# STM32H7RSxx register map
File version: 0.2
CPU: CM7 r0p1, little endian, MPU, FPU, 4 interrupt priority bits
Registers are 32-bit, read-write, reset 0x0 unless marked. A register's access mark holds for its fields unless they carry their own. Offsets are from the block's base; [hi:lo] are bit positions.

## TIM6 — Basic timers
Base 0x40001000
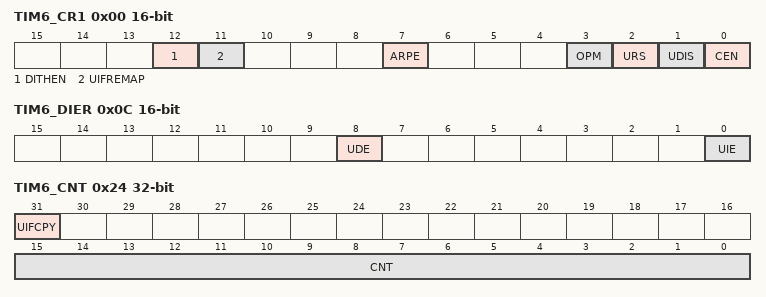
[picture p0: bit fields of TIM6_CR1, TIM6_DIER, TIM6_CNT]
0x00 TIM6_CR1 16-bit — TIM6 control register 1
  [12] DITHEN — Dithering enable Note: The DITHEN bit can only be modified when CEN bit is reset.
    0=Dithering disabled; 1=Dithering enabled
  [11] UIFREMAP — UIF status bit remapping
    0=No remapping. UIF status bit is not copied to TIMx_CNT register bit 31.; 1=Remapping enabled. UIF status bit is copied to TIMx_CNT register bit 31.
  [7] ARPE — Auto-reload preload enable
    0=TIMx_ARR register is not buffered; 1=TIMx_ARR register is buffered
  [3] OPM — One-pulse mode
    0=Counter is not stopped at update event; 1=Counter stops counting at the next update event (clearing the CEN bit)
  [2] URS — Update request source This bit is set and cleared by software to select the UEV event sources. Counter overflow/underflow Setting the UG bit Update generation through the slave mode controller
    0=Any of the following events generates an update interrupt or DMA request if enabled. These events can be:; 1=Only counter overflow/underflow generates an update interrupt or DMA request if enabled
  [1] UDIS — Update disable This bit is set and cleared by software to enable/disable UEV event generation. Counter overflow/underflow Setting the UG bit Update generation through the slave mode controller Buffered registers are then loaded with their preload values.
    0=UEV enabled. The Update (UEV) event is generated by one of the following events:; 1=UEV disabled. The Update event is not generated, shadow registers keep their value (ARR, PSC). However the counter and the prescaler are reinitialized if the UG bit is set or if a hardware reset is received from the slave mode controller.
  [0] CEN — Counter enable CEN is cleared automatically in one-pulse mode, when an update event occurs.
    0=Counter disabled; 1=Counter enabled
0x04 TIM6_CR2 16-bit — TIM6 control register 2
  [6:4] MMS — Master mode selection These bits are used to select the information to be sent in master mode to slave timers for synchronization (TRGO). The combination is as follows: Note: The clock of the slave timer or he peripheral receiving the tim_trgo must be enabled prior to receive events from the master timer, and must not be changed on-the-fly while triggers are received from the master timer.
    0=Reset - the UG bit from the TIMx_EGR register is used as a trigger output (tim_trgo); 1=Enable - the Counter enable signal, tim_cnt_en, is used as a trigger output (tim_trgo). It is useful to start several timers at the same time or to control a window in which a slave timer is enabled. The Counter Enable signal is generated when the CEN control bit is written.; 2=Update - The update event is selected as a trigger output (tim_trgo). For instance a master timer can then be used as a prescaler for a slave timer.
0x0C TIM6_DIER 16-bit — TIM6 DMA/Interrupt enable register
  [8] UDE — Update DMA request enable
    0=Update DMA request disabled; 1=Update DMA request enabled
  [0] UIE — Update interrupt enable
    0=Update interrupt disabled; 1=Update interrupt enabled
0x10 TIM6_SR 16-bit — TIM6 status register
  [0] UIF — Update interrupt flag This bit is set by hardware on an update event. It is cleared by software. On counter overflow if UDIS = 0 in the TIMx_CR1 register. When CNT is reinitialized by software using the UG bit in the TIMx_EGR register, if URS = 0 and UDIS = 0 in the TIMx_CR1 register.
    0=No update occurred; 1=Update interrupt pending. This bit is set by hardware when the registers are updated:
0x14 TIM6_EGR 16-bit wo — TIM6 event generation register
  [0] UG — Update generation This bit can be set by software, it is automatically cleared by hardware.
    0=No action; 1=Re-initializes the timer counter and generates an update of the registers. Note that the prescaler counter is cleared too (but the prescaler ratio is not affected).
0x24 TIM6_CNT access per field — TIM6 counter
  [31] UIFCPY ro — UIF copy This bit is a read-only copy of the UIF bit of the TIMx_ISR register. If the UIFREMAP bit in TIMx_CR1 is reset, bit 31 is reserved and read as 0.
  [15:0] CNT rw — Counter value Non-dithering mode (DITHEN = 0) The register holds the counter value. Dithering mode (DITHEN = 1) The register only holds the non-dithered part in CNT[15:0]. The fractional part is not available.
0x28 TIM6_PSC 16-bit — TIM6 prescaler
  [15:0] PSC — Prescaler value The counter clock frequency f<sub>tim_cnt_ck</sub> is equal to f<sub>tim_psc_ck</sub> / (PSC[15:0] + 1). PSC contains the value to be loaded into the active prescaler register at each update event. (including when the counter is cleared through UG bit of TIMx_EGR register.
0x2C TIM6_ARR reset 0xFFFF — TIM6 auto-reload register
  [19:0] ARR — Auto-reload value ARR is the value to be loaded into the actual auto-reload register. Refer to Section 66.3.4: Time-base unit on page 3923 for more details about ARR update and behavior. The counter is blocked while the auto-reload value is null. Non-dithering mode (DITHEN = 0) The register holds the auto-reload value in ARR[15:0]. The ARR[19:16] bits are reserved. Dithering mode (DITHEN = 1) The register holds the integer part in ARR[19:4]. The ARR[3:0] bitfield contains the dithered part.

## TIM7 — Basic timers
Base 0x40001400
Registers as TIM6 (with TIM6 read as TIM7).
